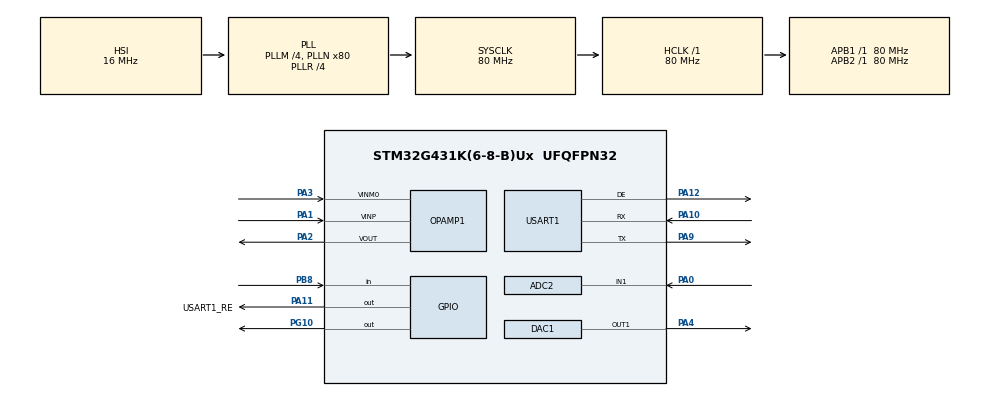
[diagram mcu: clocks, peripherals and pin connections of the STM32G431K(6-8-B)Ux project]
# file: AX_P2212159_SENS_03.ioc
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ADC1.Channel-0\#ChannelRegularConversion=ADC_CHANNEL_TEMPSENSOR_ADC1
ADC1.Channel-1\#ChannelRegularConversion=ADC_CHANNEL_VREFINT
ADC1.DMAContinuousRequests=ENABLE
ADC1.EOCSelection=ADC_EOC_SEQ_CONV
ADC1.ExternalTrigConv=ADC_EXTERNALTRIG_T7_TRGO
ADC1.NbrOfConversion=2
ADC1.NbrOfConversionFlag=1
ADC1.OffsetNumber-0\#ChannelRegularConversion=ADC_OFFSET_NONE
ADC1.OffsetNumber-1\#ChannelRegularConversion=ADC_OFFSET_NONE
ADC1.OversamplingMode=DISABLE
ADC1.Rank-0\#ChannelRegularConversion=1
ADC1.Rank-1\#ChannelRegularConversion=2
ADC1.SamplingTime-0\#ChannelRegularConversion=ADC_SAMPLETIME_92CYCLES_5
ADC1.SamplingTime-1\#ChannelRegularConversion=ADC_SAMPLETIME_92CYCLES_5
ADC1.master=1
ADC2.Channel-0\#ChannelRegularConversion=ADC_CHANNEL_1
ADC2.DMAContinuousRequests=ENABLE
ADC2.EOCSelection=ADC_EOC_SEQ_CONV
ADC2.ExternalTrigConv=ADC_EXTERNALTRIG_T6_TRGO
ADC2.NbrOfConversionFlag=1
ADC2.OffsetNumber-0\#ChannelRegularConversion=ADC_OFFSET_NONE
ADC2.OversamplingMode=DISABLE
ADC2.Rank-0\#ChannelRegularConversion=1
ADC2.SamplingTime-0\#ChannelRegularConversion=ADC_SAMPLETIME_24CYCLES_5
DAC1.DAC_Trigger_OUT1-DAC_OUT1_ExtAndInt=DAC_TRIGGER_T6_TRGO
DAC1.WaveGeneration_OUT1-DAC_OUT1_ExtAndInt=DISABLE
Dma.ADC1.1.Direction=DMA_PERIPH_TO_MEMORY
Dma.ADC1.1.EventEnable=DISABLE
Dma.ADC1.1.Instance=DMA1_Channel2
Dma.ADC1.1.MemDataAlignment=DMA_MDATAALIGN_HALFWORD
Dma.ADC1.1.MemInc=DMA_MINC_ENABLE
Dma.ADC1.1.Mode=DMA_CIRCULAR
Dma.ADC1.1.PeriphDataAlignment=DMA_PDATAALIGN_WORD
Dma.ADC1.1.PeriphInc=DMA_PINC_DISABLE
Dma.ADC1.1.Polarity=HAL_DMAMUX_REQ_GEN_RISING
Dma.ADC1.1.Priority=DMA_PRIORITY_LOW
Dma.ADC1.1.RequestNumber=1
Dma.ADC1.1.SignalID=NONE
Dma.ADC1.1.SyncEnable=DISABLE
Dma.ADC1.1.SyncPolarity=HAL_DMAMUX_SYNC_NO_EVENT
Dma.ADC1.1.SyncRequestNumber=1
Dma.ADC1.1.SyncSignalID=NONE
Dma.ADC2.2.Direction=DMA_PERIPH_TO_MEMORY
Dma.ADC2.2.EventEnable=DISABLE
Dma.ADC2.2.Instance=DMA1_Channel3
Dma.ADC2.2.MemDataAlignment=DMA_MDATAALIGN_HALFWORD
Dma.ADC2.2.MemInc=DMA_MINC_ENABLE
Dma.ADC2.2.Mode=DMA_CIRCULAR
Dma.ADC2.2.PeriphDataAlignment=DMA_PDATAALIGN_WORD
Dma.ADC2.2.PeriphInc=DMA_PINC_DISABLE
Dma.ADC2.2.Polarity=HAL_DMAMUX_REQ_GEN_RISING
Dma.ADC2.2.Priority=DMA_PRIORITY_LOW
Dma.ADC2.2.RequestNumber=1
Dma.ADC2.2.SignalID=NONE
Dma.ADC2.2.SyncEnable=DISABLE
Dma.ADC2.2.SyncPolarity=HAL_DMAMUX_SYNC_NO_EVENT
Dma.ADC2.2.SyncRequestNumber=1
Dma.ADC2.2.SyncSignalID=NONE
Dma.DAC1_CH1.0.Direction=DMA_MEMORY_TO_PERIPH
Dma.DAC1_CH1.0.EventEnable=DISABLE
Dma.DAC1_CH1.0.Instance=DMA1_Channel1
Dma.DAC1_CH1.0.MemDataAlignment=DMA_MDATAALIGN_HALFWORD
Dma.DAC1_CH1.0.MemInc=DMA_MINC_ENABLE
Dma.DAC1_CH1.0.Mode=DMA_CIRCULAR
Dma.DAC1_CH1.0.PeriphDataAlignment=DMA_PDATAALIGN_WORD
Dma.DAC1_CH1.0.PeriphInc=DMA_PINC_DISABLE
Dma.DAC1_CH1.0.Polarity=HAL_DMAMUX_REQ_GEN_RISING
Dma.DAC1_CH1.0.Priority=DMA_PRIORITY_LOW
Dma.DAC1_CH1.0.RequestNumber=1
Dma.DAC1_CH1.0.SignalID=NONE
Dma.DAC1_CH1.0.SyncEnable=DISABLE
Dma.DAC1_CH1.0.SyncPolarity=HAL_DMAMUX_SYNC_NO_EVENT
Dma.DAC1_CH1.0.SyncRequestNumber=1
Dma.DAC1_CH1.0.SyncSignalID=NONE
Dma.Request0=DAC1_CH1
Dma.Request1=ADC1
Dma.Request2=ADC2
Mcu.Family=STM32G4
Mcu.Name=STM32G431K(6-8-B)Ux
Mcu.Package=UFQFPN32
NVIC.DMA1_Channel1_IRQn=true\:0\:0\:false\:false\:true\:false\:true\:true
NVIC.DMA1_Channel2_IRQn=true\:0\:0\:false\:false\:true\:false\:true\:true
NVIC.DMA1_Channel3_IRQn=true\:0\:0\:false\:false\:true\:false\:true\:true
NVIC.PriorityGroup=NVIC_PRIORITYGROUP_4
NVIC.USART1_IRQn=true\:0\:0\:false\:false\:true\:true\:true\:true
OPAMP1.SelfCalibration=Enable
OPAMP1.UserTrimming=OPAMP_TRIMMING_USER
PA0.Mode=IN1-Single-Ended
PA0.Signal=ADC2_IN1
PA1.Mode=PGA Connected
PA1.Signal=OPAMP1_VINP
PA10.Mode=Asynchronous
PA10.Signal=USART1_RX
PA11.GPIO_Label=USART1_RE
PA11.PinState=GPIO_PIN_SET
PA11.Signal=GPIO_Output
PA12.Mode=Hardware Flow Control (RS485)
PA12.Signal=USART1_DE
PA13.Mode=Serial_Wire
PA13.Signal=SYS_JTMS-SWDIO
PA14.Mode=Serial_Wire
PA14.Signal=SYS_JTCK-SWCLK
PA2.Mode=PGA Connected
PA2.Signal=OPAMP1_VOUT
PA3.Mode=PGA Connected
PA3.Signal=OPAMP1_VINM0
PA4.Signal=COMP_DAC11_group
PA9.Mode=Asynchronous
PA9.Signal=USART1_TX
PB8-BOOT0.GPIO_PuPd=GPIO_PULLDOWN
PB8-BOOT0.Signal=GPIO_Input
PG10-NRST.Signal=GPIO_Output
ProjectManager.HeapSize=0x200
ProjectManager.StackSize=0x400
ProjectManager.TargetToolchain=STM32CubeIDE
RCC.ADC12Freq_Value=80000000
RCC.AHBFreq_Value=80000000
RCC.APB1Freq_Value=80000000
RCC.APB1TimFreq_Value=80000000
RCC.APB2Freq_Value=80000000
RCC.APB2TimFreq_Value=80000000
RCC.CortexFreq_Value=80000000
RCC.EXTERNAL_CLOCK_VALUE=12288000
RCC.HCLKFreq_Value=80000000
RCC.HSE_VALUE=8000000
RCC.HSI48_VALUE=48000000
RCC.HSI_VALUE=16000000
RCC.LSE_VALUE=32768
RCC.PLLM=RCC_PLLM_DIV4
RCC.PLLN=80
RCC.PLLR=RCC_PLLR_DIV4
RCC.SYSCLKFreq_VALUE=80000000
RCC.SYSCLKSource=RCC_SYSCLKSOURCE_PLLCLK
RCC.USBFreq_Value=160000000
RCC.VCOOutputFreq_Value=320000000
SH.COMP_DAC11_group.0=DAC1_OUT1,DAC_OUT1_ExtAndInt
TIM17.PeriodNoDither=10000
TIM17.Prescaler=80
TIM6.PeriodNoDither=200
TIM6.Prescaler=0
TIM6.TIM_MasterOutputTrigger=TIM_TRGO_UPDATE
TIM7.PeriodNoDither=20
TIM7.Prescaler=20
TIM7.TIM_MasterOutputTrigger=TIM_TRGO_UPDATE
USART1.VirtualMode-Asynchronous=VM_ASYNC
USART1.VirtualMode-Hardware\ Flow\ Control\ (RS485)=VM_ASYNC
VP_ADC1_TempSens_Input.Mode=IN-TempSens
VP_ADC1_Vref_Input.Mode=IN-Vrefint
VP_TIM17_VS_ClockSourceINT.Mode=Enable_Timer
VP_TIM6_VS_ClockSourceINT.Mode=Enable_Timer
VP_TIM7_VS_ClockSourceINT.Mode=Enable_Timer
board=custom

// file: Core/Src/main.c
/* USER CODE BEGIN Header */
/**
  ******************************************************************************
  * @file           : main.c
  * @brief          : Main program body
  ******************************************************************************
  * @attention
  *
  * Copyright (c) 2024 STMicroelectronics.
  * All rights reserved.
  *
  * This software is licensed under terms that can be found in the LICENSE file
  * in the root directory of this software component.
  * If no LICENSE file comes with this software, it is provided AS-IS.
  *
  ******************************************************************************
  */
/* USER CODE END Header */
#include "main.h"

ADC_HandleTypeDef hadc1;
ADC_HandleTypeDef hadc2;
DMA_HandleTypeDef hdma_adc1;
DMA_HandleTypeDef hdma_adc2;

DAC_HandleTypeDef hdac1;
DMA_HandleTypeDef hdma_dac1_ch1;

OPAMP_HandleTypeDef hopamp1;

TIM_HandleTypeDef htim6;
TIM_HandleTypeDef htim7;
TIM_HandleTypeDef htim17;

UART_HandleTypeDef huart1;

void SystemClock_Config(void);
static void MX_GPIO_Init(void);
static void MX_DMA_Init(void);
static void MX_ADC1_Init(void);
static void MX_DAC1_Init(void);
static void MX_OPAMP1_Init(void);
static void MX_USART1_UART_Init(void);
static void MX_TIM6_Init(void);
static void MX_TIM17_Init(void);
static void MX_ADC2_Init(void);
static void MX_TIM7_Init(void);

int main(void)
{

  /* MCU Configuration--------------------------------------------------------*/

  /* Reset of all peripherals, Initializes the Flash interface and the Systick. */
  HAL_Init();

  /* Configure the system clock */
  SystemClock_Config();

  /* Initialize all configured peripherals */
  MX_GPIO_Init();
  MX_DMA_Init();
  MX_ADC1_Init();
  MX_DAC1_Init();
  MX_OPAMP1_Init();
  MX_USART1_UART_Init();
  MX_TIM6_Init();
  MX_TIM17_Init();
  MX_ADC2_Init();
  MX_TIM7_Init();
  /* USER CODE BEGIN 2 */
  SensorInit();

  /* USER CODE END 2 */

  /* Infinite loop */
  /* USER CODE BEGIN WHILE */
  while (1)
  {
	  SensorLoop();

    /* USER CODE END WHILE */

  }
}

void SystemClock_Config(void)
{
  RCC_OscInitTypeDef RCC_OscInitStruct = {0};
  RCC_ClkInitTypeDef RCC_ClkInitStruct = {0};

  /** Configure the main internal regulator output voltage
  */
  HAL_PWREx_ControlVoltageScaling(PWR_REGULATOR_VOLTAGE_SCALE1);

  /** Initializes the RCC Oscillators according to the specified parameters
  * in the RCC_OscInitTypeDef structure.
  */
  RCC_OscInitStruct.OscillatorType = RCC_OSCILLATORTYPE_HSI;
  RCC_OscInitStruct.HSIState = RCC_HSI_ON;
  RCC_OscInitStruct.HSICalibrationValue = RCC_HSICALIBRATION_DEFAULT;
  RCC_OscInitStruct.PLL.PLLState = RCC_PLL_ON;
  RCC_OscInitStruct.PLL.PLLSource = RCC_PLLSOURCE_HSI;
  RCC_OscInitStruct.PLL.PLLM = RCC_PLLM_DIV4;
  RCC_OscInitStruct.PLL.PLLN = 80;
  RCC_OscInitStruct.PLL.PLLP = RCC_PLLP_DIV2;
  RCC_OscInitStruct.PLL.PLLQ = RCC_PLLQ_DIV2;
  RCC_OscInitStruct.PLL.PLLR = RCC_PLLR_DIV4;
  if (HAL_RCC_OscConfig(&RCC_OscInitStruct) != HAL_OK)
  {
    Error_Handler();
  }

  /** Initializes the CPU, AHB and APB buses clocks
  */
  RCC_ClkInitStruct.ClockType = RCC_CLOCKTYPE_HCLK|RCC_CLOCKTYPE_SYSCLK
                              |RCC_CLOCKTYPE_PCLK1|RCC_CLOCKTYPE_PCLK2;
  RCC_ClkInitStruct.SYSCLKSource = RCC_SYSCLKSOURCE_PLLCLK;
  RCC_ClkInitStruct.AHBCLKDivider = RCC_SYSCLK_DIV1;
  RCC_ClkInitStruct.APB1CLKDivider = RCC_HCLK_DIV1;
  RCC_ClkInitStruct.APB2CLKDivider = RCC_HCLK_DIV1;

  if (HAL_RCC_ClockConfig(&RCC_ClkInitStruct, FLASH_LATENCY_2) != HAL_OK)
  {
    Error_Handler();
  }
}

static void MX_ADC1_Init(void)
{

  ADC_MultiModeTypeDef multimode = {0};
  ADC_ChannelConfTypeDef sConfig = {0};

  /** Common config
  */
  hadc1.Instance = ADC1;
  hadc1.Init.ClockPrescaler = ADC_CLOCK_SYNC_PCLK_DIV2;
  hadc1.Init.Resolution = ADC_RESOLUTION_12B;
  hadc1.Init.DataAlign = ADC_DATAALIGN_RIGHT;
  hadc1.Init.GainCompensation = 0;
  hadc1.Init.ScanConvMode = ADC_SCAN_ENABLE;
  hadc1.Init.EOCSelection = ADC_EOC_SEQ_CONV;
  hadc1.Init.LowPowerAutoWait = DISABLE;
  hadc1.Init.ContinuousConvMode = DISABLE;
  hadc1.Init.NbrOfConversion = 2;
  hadc1.Init.DiscontinuousConvMode = DISABLE;
  hadc1.Init.ExternalTrigConv = ADC_EXTERNALTRIG_T7_TRGO;
  hadc1.Init.ExternalTrigConvEdge = ADC_EXTERNALTRIGCONVEDGE_RISING;
  hadc1.Init.DMAContinuousRequests = ENABLE;
  hadc1.Init.Overrun = ADC_OVR_DATA_PRESERVED;
  hadc1.Init.OversamplingMode = DISABLE;
  if (HAL_ADC_Init(&hadc1) != HAL_OK)
  {
    Error_Handler();
  }

  /** Configure the ADC multi-mode
  */
  multimode.Mode = ADC_MODE_INDEPENDENT;
  if (HAL_ADCEx_MultiModeConfigChannel(&hadc1, &multimode) != HAL_OK)
  {
    Error_Handler();
  }

  /** Configure Regular Channel
  */
  sConfig.Channel = ADC_CHANNEL_TEMPSENSOR_ADC1;
  sConfig.Rank = ADC_REGULAR_RANK_1;
  sConfig.SamplingTime = ADC_SAMPLETIME_92CYCLES_5;
  sConfig.SingleDiff = ADC_SINGLE_ENDED;
  sConfig.OffsetNumber = ADC_OFFSET_NONE;
  sConfig.Offset = 0;
  if (HAL_ADC_ConfigChannel(&hadc1, &sConfig) != HAL_OK)
  {
    Error_Handler();
  }

  /** Configure Regular Channel
  */
  sConfig.Channel = ADC_CHANNEL_VREFINT;
  sConfig.Rank = ADC_REGULAR_RANK_2;
  if (HAL_ADC_ConfigChannel(&hadc1, &sConfig) != HAL_OK)
  {
    Error_Handler();
  }

}

static void MX_ADC2_Init(void)
{

  ADC_ChannelConfTypeDef sConfig = {0};

  /** Common config
  */
  hadc2.Instance = ADC2;
  hadc2.Init.ClockPrescaler = ADC_CLOCK_SYNC_PCLK_DIV2;
  hadc2.Init.Resolution = ADC_RESOLUTION_12B;
  hadc2.Init.DataAlign = ADC_DATAALIGN_RIGHT;
  hadc2.Init.GainCompensation = 0;
  hadc2.Init.ScanConvMode = ADC_SCAN_DISABLE;
  hadc2.Init.EOCSelection = ADC_EOC_SEQ_CONV;
  hadc2.Init.LowPowerAutoWait = DISABLE;
  hadc2.Init.ContinuousConvMode = DISABLE;
  hadc2.Init.NbrOfConversion = 1;
  hadc2.Init.DiscontinuousConvMode = DISABLE;
  hadc2.Init.ExternalTrigConv = ADC_EXTERNALTRIG_T6_TRGO;
  hadc2.Init.ExternalTrigConvEdge = ADC_EXTERNALTRIGCONVEDGE_RISING;
  hadc2.Init.DMAContinuousRequests = ENABLE;
  hadc2.Init.Overrun = ADC_OVR_DATA_PRESERVED;
  hadc2.Init.OversamplingMode = DISABLE;
  if (HAL_ADC_Init(&hadc2) != HAL_OK)
  {
    Error_Handler();
  }

  /** Configure Regular Channel
  */
  sConfig.Channel = ADC_CHANNEL_1;
  sConfig.Rank = ADC_REGULAR_RANK_1;
  sConfig.SamplingTime = ADC_SAMPLETIME_24CYCLES_5;
  sConfig.SingleDiff = ADC_SINGLE_ENDED;
  sConfig.OffsetNumber = ADC_OFFSET_NONE;
  sConfig.Offset = 0;
  if (HAL_ADC_ConfigChannel(&hadc2, &sConfig) != HAL_OK)
  {
    Error_Handler();
  }

}

static void MX_DAC1_Init(void)
{

  DAC_ChannelConfTypeDef sConfig = {0};

  /** DAC Initialization
  */
  hdac1.Instance = DAC1;
  if (HAL_DAC_Init(&hdac1) != HAL_OK)
  {
    Error_Handler();
  }

  /** DAC channel OUT1 config
  */
  sConfig.DAC_HighFrequency = DAC_HIGH_FREQUENCY_INTERFACE_MODE_AUTOMATIC;
  sConfig.DAC_DMADoubleDataMode = DISABLE;
  sConfig.DAC_SignedFormat = DISABLE;
  sConfig.DAC_SampleAndHold = DAC_SAMPLEANDHOLD_DISABLE;
  sConfig.DAC_Trigger = DAC_TRIGGER_T6_TRGO;
  sConfig.DAC_Trigger2 = DAC_TRIGGER_NONE;
  sConfig.DAC_OutputBuffer = DAC_OUTPUTBUFFER_ENABLE;
  sConfig.DAC_ConnectOnChipPeripheral = DAC_CHIPCONNECT_BOTH;
  sConfig.DAC_UserTrimming = DAC_TRIMMING_FACTORY;
  if (HAL_DAC_ConfigChannel(&hdac1, &sConfig, DAC_CHANNEL_1) != HAL_OK)
  {
    Error_Handler();
  }

}

static void MX_OPAMP1_Init(void)
{

  hopamp1.Instance = OPAMP1;
  hopamp1.Init.PowerMode = OPAMP_POWERMODE_NORMAL;
  hopamp1.Init.Mode = OPAMP_PGA_MODE;
  hopamp1.Init.NonInvertingInput = OPAMP_NONINVERTINGINPUT_IO0;
  hopamp1.Init.InternalOutput = DISABLE;
  hopamp1.Init.TimerControlledMuxmode = OPAMP_TIMERCONTROLLEDMUXMODE_DISABLE;
  hopamp1.Init.PgaConnect = OPAMP_PGA_CONNECT_INVERTINGINPUT_IO0;
  hopamp1.Init.PgaGain = OPAMP_PGA_GAIN_2_OR_MINUS_1;
  hopamp1.Init.UserTrimming = OPAMP_TRIMMING_USER;
  if (HAL_OPAMP_Init(&hopamp1) != HAL_OK)
  {
    Error_Handler();
  }
  if (HAL_OPAMP_SelfCalibrate(&hopamp1) != HAL_OK)
  {
    Error_Handler();
  }

}

static void MX_TIM6_Init(void)
{

  TIM_MasterConfigTypeDef sMasterConfig = {0};

  htim6.Instance = TIM6;
  htim6.Init.Prescaler = 0;
  htim6.Init.CounterMode = TIM_COUNTERMODE_UP;
  htim6.Init.Period = 200;
  htim6.Init.AutoReloadPreload = TIM_AUTORELOAD_PRELOAD_DISABLE;
  if (HAL_TIM_Base_Init(&htim6) != HAL_OK)
  {
    Error_Handler();
  }
  sMasterConfig.MasterOutputTrigger = TIM_TRGO_UPDATE;
  sMasterConfig.MasterSlaveMode = TIM_MASTERSLAVEMODE_DISABLE;
  if (HAL_TIMEx_MasterConfigSynchronization(&htim6, &sMasterConfig) != HAL_OK)
  {
    Error_Handler();
  }

}

static void MX_TIM7_Init(void)
{

  TIM_MasterConfigTypeDef sMasterConfig = {0};

  htim7.Instance = TIM7;
  htim7.Init.Prescaler = 20;
  htim7.Init.CounterMode = TIM_COUNTERMODE_UP;
  htim7.Init.Period = 20;
  htim7.Init.AutoReloadPreload = TIM_AUTORELOAD_PRELOAD_DISABLE;
  if (HAL_TIM_Base_Init(&htim7) != HAL_OK)
  {
    Error_Handler();
  }
  sMasterConfig.MasterOutputTrigger = TIM_TRGO_UPDATE;
  sMasterConfig.MasterSlaveMode = TIM_MASTERSLAVEMODE_DISABLE;
  if (HAL_TIMEx_MasterConfigSynchronization(&htim7, &sMasterConfig) != HAL_OK)
  {
    Error_Handler();
  }

}

static void MX_TIM17_Init(void)
{

  htim17.Instance = TIM17;
  htim17.Init.Prescaler = 80;
  htim17.Init.CounterMode = TIM_COUNTERMODE_UP;
  htim17.Init.Period = 10000;
  htim17.Init.ClockDivision = TIM_CLOCKDIVISION_DIV1;
  htim17.Init.RepetitionCounter = 0;
  htim17.Init.AutoReloadPreload = TIM_AUTORELOAD_PRELOAD_DISABLE;
  if (HAL_TIM_Base_Init(&htim17) != HAL_OK)
  {
    Error_Handler();
  }

}

static void MX_USART1_UART_Init(void)
{

  huart1.Instance = USART1;
  huart1.Init.BaudRate = 115200;
  huart1.Init.WordLength = UART_WORDLENGTH_8B;
  huart1.Init.StopBits = UART_STOPBITS_1;
  huart1.Init.Parity = UART_PARITY_NONE;
  huart1.Init.Mode = UART_MODE_TX_RX;
  huart1.Init.HwFlowCtl = UART_HWCONTROL_NONE;
  huart1.Init.OverSampling = UART_OVERSAMPLING_16;
  huart1.Init.OneBitSampling = UART_ONE_BIT_SAMPLE_DISABLE;
  huart1.Init.ClockPrescaler = UART_PRESCALER_DIV1;
  huart1.AdvancedInit.AdvFeatureInit = UART_ADVFEATURE_NO_INIT;
  if (HAL_RS485Ex_Init(&huart1, UART_DE_POLARITY_HIGH, 0, 0) != HAL_OK)
  {
    Error_Handler();
  }
  if (HAL_UARTEx_SetTxFifoThreshold(&huart1, UART_TXFIFO_THRESHOLD_1_8) != HAL_OK)
  {
    Error_Handler();
  }
  if (HAL_UARTEx_SetRxFifoThreshold(&huart1, UART_RXFIFO_THRESHOLD_1_8) != HAL_OK)
  {
    Error_Handler();
  }
  if (HAL_UARTEx_DisableFifoMode(&huart1) != HAL_OK)
  {
    Error_Handler();
  }

}

static void MX_DMA_Init(void)
{

  /* DMA controller clock enable */
  __HAL_RCC_DMAMUX1_CLK_ENABLE();
  __HAL_RCC_DMA1_CLK_ENABLE();

  /* DMA interrupt init */
  /* DMA1_Channel1_IRQn interrupt configuration */
  HAL_NVIC_SetPriority(DMA1_Channel1_IRQn, 0, 0);
  HAL_NVIC_EnableIRQ(DMA1_Channel1_IRQn);
  /* DMA1_Channel2_IRQn interrupt configuration */
  HAL_NVIC_SetPriority(DMA1_Channel2_IRQn, 0, 0);
  HAL_NVIC_EnableIRQ(DMA1_Channel2_IRQn);
  /* DMA1_Channel3_IRQn interrupt configuration */
  HAL_NVIC_SetPriority(DMA1_Channel3_IRQn, 0, 0);
  HAL_NVIC_EnableIRQ(DMA1_Channel3_IRQn);

}

static void MX_GPIO_Init(void)
{
  GPIO_InitTypeDef GPIO_InitStruct = {0};

  /* GPIO Ports Clock Enable */
  __HAL_RCC_GPIOG_CLK_ENABLE();
  __HAL_RCC_GPIOA_CLK_ENABLE();
  __HAL_RCC_GPIOB_CLK_ENABLE();

  /*Configure GPIO pin Output Level */
  HAL_GPIO_WritePin(GPIOG, GPIO_PIN_10, GPIO_PIN_RESET);

  /*Configure GPIO pin Output Level */
  HAL_GPIO_WritePin(USART1_RE_GPIO_Port, USART1_RE_Pin, GPIO_PIN_SET);

  /*Configure GPIO pin : PG10 */
  GPIO_InitStruct.Pin = GPIO_PIN_10;
  GPIO_InitStruct.Mode = GPIO_MODE_OUTPUT_PP;
  GPIO_InitStruct.Pull = GPIO_NOPULL;
  GPIO_InitStruct.Speed = GPIO_SPEED_FREQ_LOW;
  HAL_GPIO_Init(GPIOG, &GPIO_InitStruct);

  /*Configure GPIO pin : USART1_RE_Pin */
  GPIO_InitStruct.Pin = USART1_RE_Pin;
  GPIO_InitStruct.Mode = GPIO_MODE_OUTPUT_PP;
  GPIO_InitStruct.Pull = GPIO_NOPULL;
  GPIO_InitStruct.Speed = GPIO_SPEED_FREQ_LOW;
  HAL_GPIO_Init(USART1_RE_GPIO_Port, &GPIO_InitStruct);

  /*Configure GPIO pin : PB8 */
  GPIO_InitStruct.Pin = GPIO_PIN_8;
  GPIO_InitStruct.Mode = GPIO_MODE_INPUT;
  GPIO_InitStruct.Pull = GPIO_PULLDOWN;
  HAL_GPIO_Init(GPIOB, &GPIO_InitStruct);

}

void Error_Handler(void)
{
  __disable_irq();
  while (1)
  {
  }
}
